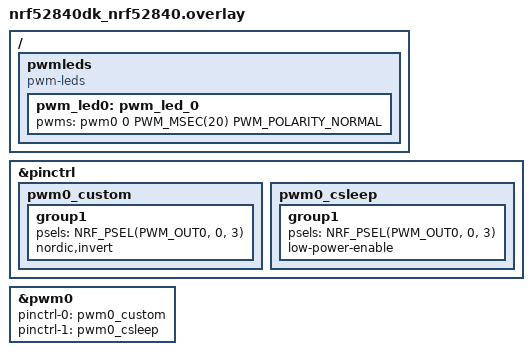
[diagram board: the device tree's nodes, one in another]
// To get started, press Ctrl+Space to bring up the completion menu and view the available nodes.

// You can also use the buttons in the sidebar to perform actions on nodes.
// Actions currently available include:

// * Enabling / disabling the node
// * Adding the bus to a bus
// * Removing the node
// * Connecting ADC channels

// For more help, browse the DeviceTree documentation at https://docs.zephyrproject.org/latest/guides/dts/index.html
// You can also visit the nRF DeviceTree extension documentation at https://docs.nordicsemi.com/bundle/nrf-connect-vscode/page/guides/ncs_configure_app.html#devicetree-support-in-the-extension

/* Step 3.1.3  */
&pinctrl {
    pwm0_custom: pwm0_custom {
        group1 {
            psels = <NRF_PSEL(PWM_OUT0, 0, 3)>;
            nordic,invert;
        };
    };

    pwm0_csleep: pwm0_csleep {
        group1 {
            psels = <NRF_PSEL(PWM_OUT0, 0, 3)>;
            low-power-enable;
        };
    };
};
/* Step 3.1.2  */
&pwm0 {
    status = "okay";
    pinctrl-0 = <&pwm0_custom>;
    pinctrl-1 = <&pwm0_csleep>;
    pinctrl-names = "default", "sleep";
};

/* Step 3.1.1  */
/{
    pwmleds {
        compatible = "pwm-leds";
        pwm_led0: pwm_led_0 {
            pwms = <&pwm0 0 PWM_MSEC(20) PWM_POLARITY_NORMAL>;
        };
    };
};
